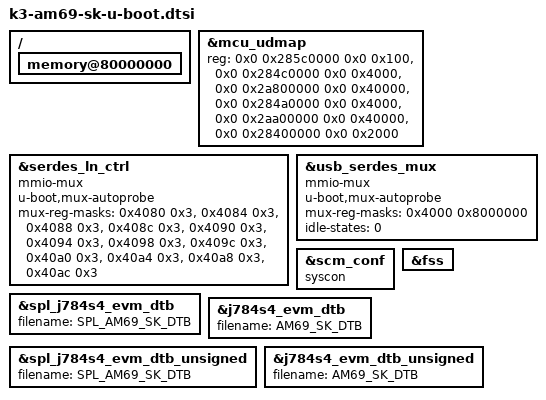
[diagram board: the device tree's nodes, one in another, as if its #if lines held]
// SPDX-License-Identifier: GPL-2.0-only
/*
 * Copyright (C) 2022-2023 Texas Instruments Incorporated - https://www.ti.com/
 */

#include "k3-j784s4-binman.dtsi"

/ {
	memory@80000000 {
		bootph-all;
	};
};

&mcu_udmap {
	reg =   <0x0 0x285c0000 0x0 0x100>,
		<0x0 0x284c0000 0x0 0x4000>,
		<0x0 0x2a800000 0x0 0x40000>,
		<0x0 0x284a0000 0x0 0x4000>,
		<0x0 0x2aa00000 0x0 0x40000>,
		<0x0 0x28400000 0x0 0x2000>;
	reg-names = "gcfg", "rchan", "rchanrt", "tchan",
		    "tchanrt", "rflow";
	bootph-pre-ram;
};

&serdes_ln_ctrl {
	u-boot,mux-autoprobe;
	compatible = "mmio-mux";
	mux-reg-masks = <0x4080 0x3>, <0x4084 0x3>, /* SERDES0 lane0/1 select */
			<0x4088 0x3>, <0x408c 0x3>, /* SERDES0 lane2/3 select */
			<0x4090 0x3>, <0x4094 0x3>, /* SERDES1 lane0/1 select */
			<0x4098 0x3>, <0x409c 0x3>, /* SERDES1 lane2/3 select */
			<0x40a0 0x3>, <0x40a4 0x3>, /* SERDES2 lane0/1 select */
			<0x40a8 0x3>, <0x40ac 0x3>; /* SERDES2 lane2/3 select */
};

&usb_serdes_mux {
	u-boot,mux-autoprobe;
	compatible = "mmio-mux";
	mux-reg-masks = <0x4000 0x8000000>; /* USB0 to SERDES0 lane 1/3 mux */
	idle-states = <0>; /* USB0 to SERDES0 */
};

&scm_conf {
	compatible = "syscon", "simple-mfd";
};

&fss {
	bootph-all;
	status = "okay";
};

#ifdef CONFIG_TARGET_J784S4_A72_EVM

#define SPL_AM69_SK_DTB "spl/dts/k3-am69-sk.dtb"
#define AM69_SK_DTB "u-boot.dtb"

&spl_j784s4_evm_dtb {
	filename = SPL_AM69_SK_DTB;
};

&j784s4_evm_dtb {
	filename = AM69_SK_DTB;
};

&spl_j784s4_evm_dtb_unsigned {
	filename = SPL_AM69_SK_DTB;
};

&j784s4_evm_dtb_unsigned {
	filename = AM69_SK_DTB;
};

#endif
